# ble_top_secure register map
Vendor: Texas Instruments
Peripheral module from a debugger description file (folder CC35X1).
Registers are 32-bit, read-write, reset 0x0 unless marked. A register's access mark holds for its fields unless they carry their own. Offsets are as the file gives them; lines under a group give offsets from that group; [hi:lo] are bit positions; {n}, {i} and the like mark numbered series; 'fields as' and 'values as' point back to an identical list; <NAME> marks a mode.

## ble_top_secure
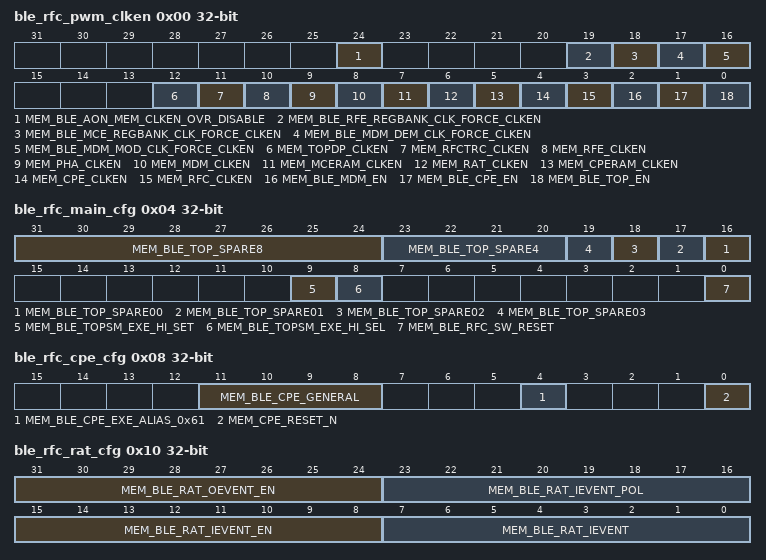
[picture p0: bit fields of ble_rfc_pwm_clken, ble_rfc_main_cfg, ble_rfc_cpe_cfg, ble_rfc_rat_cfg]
0x00 ble_rfc_pwm_clken access per field reset not defined — RF Core Power Management and Clock Enable
  [24] MEM_BLE_AON_MEM_CLKEN_OVR_DISABLE rw — Disable AON Option to Force all CLKEN to '1' on power-up, by ble_aon_mem_clken_ovr (= ble_aon_general[0]). So CLK-EN will be directed controled by BLE_RFC_PWM_CLKEN Fields: MEM_*_CLKEN, as ecpected.
  [19] MEM_BLE_RFE_REGBANK_CLK_FORCE_CLKEN rw — To force RFE REGBANK CLK to be exactly the same as MDM_CLK (as Agama Legacy) set this REG to '1'. Otherwise - for power saving RFE REGBANK CLK will be active only on WRITE Cycles. This REG - cancel RFE REGBANK CLK power saving option.
  [18] MEM_BLE_MCE_REGBANK_CLK_FORCE_CLKEN rw — To force MCE REGBANK CLK to be exactly the same as MDM_CLK (as Agama Legacy) set this REG to '1'. Otherwise - for power saving MCE REGBANK CLK will be active only on WRITE Cycles. This REG - cancel MCE REGBANK CLK power saving option.
  [17] MEM_BLE_MDM_DEM_CLK_FORCE_CLKEN rw — To force DEM_CLK to be exactly the same as MDM_CLK (as Agama Legacy) set this REG to '1'. MDM Demodulator Clock (DEM_CLK) source is MDM_CLK. (controled by mem_mdm_clken). For power saving DEM_CLK Enabled when Demodulator is Enabled by MCE REG: MDMENABLE.demodulator. This REG - Cancel DEM_CLK power saving option.
  [16] MEM_BLE_MDM_MOD_CLK_FORCE_CLKEN rw — To force MOD_CLK to be exactly the same as MDM_CLK (as Agama Legacy) set this REG to '1'. MDM Modulator Clock (MOD_CLK) source is MDM_CLK. (controled by mem_mdm_clken). For power saving MOD_CLK Enabled when Modulator is Enabled by MCE REG: MDMENABLE.modulator. This REG - Cancel MOD_CLK power saving option.
  [12] MEM_TOPDP_CLKEN rw — Enable clock to the TOP Debug-Port module. This module sample the debug-port after the mux out.
  [11] MEM_RFCTRC_CLKEN rw — Enable clock to the RF Core Tracer (RFCTRC) module.
  [10] MEM_RFE_CLKEN rw — Enable clock to the RF Engine (mem_rfe_clken) module.
  [9] MEM_PHA_CLKEN rw — Enable clock to the Packet Handling Accelerator (PHA) module.
  [8] MEM_MDM_CLKEN rw — Enable clock to the Modem (mem_mdm_clken) module.
  [7] MEM_MCERAM_CLKEN rw — Enable clock to the Modem RAM module (includes the MCE RAM).
  [6] MEM_RAT_CLKEN rw — Enable clock to the Radio Timer (RAT) module.
  [5] MEM_CPERAM_CLKEN rw — Enable clock to the Command and Packet Engine (CPE) RAM module. As part of RF Core initialization, set this bit together with CPE bit to enable CPE to boot.
  [4] MEM_CPE_CLKEN rw — Enable processor clock (hclk) to the Command and Packet Engine (mem_cpe_clken) As part of RF Core initialization, set this bit together with mem_cperam_clken to enable CPE to boot.
  [3] MEM_RFC_CLKEN ro — Enable essential clocks for the RF Core interface - This includes: - Interconnect - Radio doorbell - DBELL command interface - Power management (PWR) clock control module - Bus clock (sclk) for the CPE To remove possibility of locking yourself out from the RF Core, this bit can not be cleared. If you need to disable all clocks to the RF Core, see the WLAN.WSOC register: ble_rfc_clken If you need to disable all clocks to the RF Core MDM, see the WLAN.WSOC register: ble_rfc_mdm_clken
  [2] MEM_BLE_MDM_EN rw — MAIN Enable of the MDM Subsystem
  [1] MEM_BLE_CPE_EN rw — MAIN Enable of the CPE Subsystem
  [0] MEM_BLE_TOP_EN rw — MAIN BLE-TOP Enable
0x04 ble_rfc_main_cfg access per field — BLE RF-Core Main Configuration Register
  [31:24] MEM_BLE_TOP_SPARE8 rw — BLE_TOP BTRL Spare Register for ECO
  [23:20] MEM_BLE_TOP_SPARE4 rw — BLE_TOP BTRL Spare Register for ECO
  [n+16] MEM_BLE_TOP_SPARE{n:02} rw (n=0..3) — BLE_TOP BTRL Spare Register for ECO
  [9] MEM_BLE_TOPSM_EXE_HI_SET rw — When BLE_RFC_MAIN_CFG.mem_ble_topsm_exe_hi_sel is set to '1' , control option of TOPsm execution from high section ram (lines 512-1023): 0: MCE TOPsm execution from low section - ram lines 0-511. 1: MCE TOPsm execution from high section - ram lines 512-1023.
  [8] MEM_BLE_TOPSM_EXE_HI_SEL rw — Force option to take control of TOPsm execution from high section ram (lines 512-1023): 0: TOPsm execution from high section set by MCE MDMAPI.protocolmemalloc register. 1: BLE_RFC_MAIN_CFG.mem_ble_topsm_exe_hi_set is controlling execution from high section.
  [0] MEM_BLE_RFC_SW_RESET rw — Force a RF-CORE SW Reset - When this signal set to '1' - it Force '0' on the main RFC Reset
0x08 ble_rfc_cpe_cfg access per field reset not defined — CPE Config register
  [11:8] MEM_BLE_CPE_GENERAL rw — For CPE General Configuratioins. (in Osprey Lx it was connected to BLE_RFC_MAIN_DFG.mem_ble_top_spare4) Bit 0 - Connected as Enable to CPE EDBGRQ. Bit 1 - Spare. Bit 2 - Spare. Bit 3 - Spare.
  [4] MEM_BLE_CPE_EXE_ALIAS_0x61 rw — For protection and correct address space for execution - shift addr to 0x61.
  [0] MEM_CPE_RESET_N rw — CPE Reset_N signal - control the CM0+ main reset: when '0' Reset is active.
0x0C ble_rfc_cpe_irq_ovr wo reset not defined — CPE IRQ Overide option
  [31:0] MEM_BLE_RFC_CPE_IRQ_OVR_WRCL — CPE IRQ Overide Register.
0x10 ble_rfc_rat_cfg — BLE RAT Configuration settings
  [31:24] MEM_BLE_RAT_OEVENT_EN — BLE RF-Core RAT External Output Event Enable bus
  [23:16] MEM_BLE_RAT_IEVENT_POL — BLE RF-Core RAT External Input Event Signal Polarity bus. When a bit is set - the correlated signal is inverted.
  [15:8] MEM_BLE_RAT_IEVENT_EN — BLE RF-Core RAT External Input Event Enable bus
  [7:0] MEM_BLE_RAT_IEVENT — BLE RF-Core RAT External Input Events for Timing synch and controls
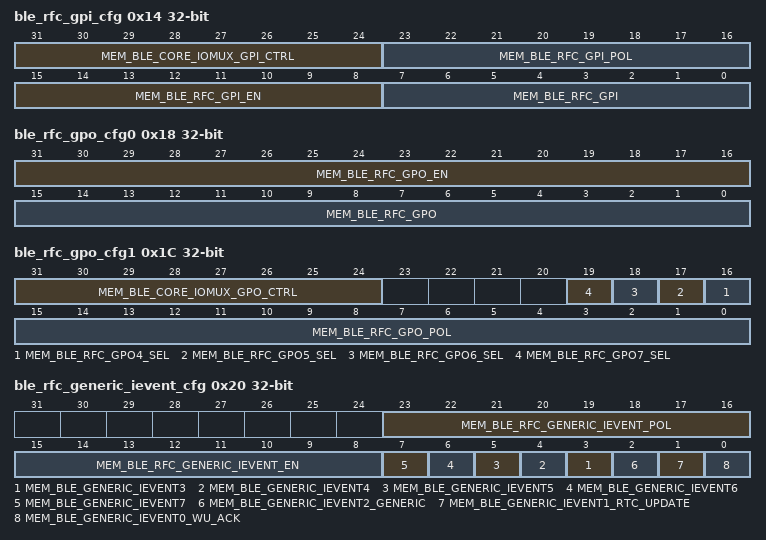
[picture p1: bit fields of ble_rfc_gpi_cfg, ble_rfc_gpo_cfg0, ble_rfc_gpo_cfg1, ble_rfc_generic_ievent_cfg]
0x14 ble_rfc_gpi_cfg — BLE GPI Configuration settings
  [31:24] MEM_BLE_CORE_IOMUX_GPI_CTRL — BLE Option to Control the CORE_IOMUX GPI. This control of external module requiered in order to connect additional BLE-GPI to main SoC IOMUX.
  [23:16] MEM_BLE_RFC_GPI_POL — BLE RF-Core GPI Signal Polarity bus. When a bit is set - the correlated signal is inverted.
  [15:8] MEM_BLE_RFC_GPI_EN — BLE RF-Core GPI Enable bus
  [7:0] MEM_BLE_RFC_GPI — BLE RF-Core GPI Overide by SW values
0x18 ble_rfc_gpo_cfg0 reset not defined — BLE GPO Configuration settings
  [31:16] MEM_BLE_RFC_GPO_EN — BLE RF-Core GPO Enable bus When a bit is set - the correlated signal is Enabled for output I/F.
  [15:0] MEM_BLE_RFC_GPO — BLE RF-Core GPO Overide by SW values
0x1C ble_rfc_gpo_cfg1 access per field — BLE GPO Configuration settings
  [31:24] MEM_BLE_CORE_IOMUX_GPO_CTRL rw — BLE Option to Control the CORE_IOMUX GPO. This control of external module requiered in order to connect additional BLE-GPO to main SoC IOMUX.
  [n+12] MEM_BLE_RFC_GPO{n}_SEL rw (n=4..7) — Selects GPO4: '0' output rfc_gpo[{n}] , '1' output rfc_gpo[{n+4}]
  [15:0] MEM_BLE_RFC_GPO_POL rw — BLE RF-Core GPO Signal Polarity bus. When a bit is set - the correlated signal is inverted for output I/F.
0x20 ble_rfc_generic_ievent_cfg access per field reset not defined — BLE GPI Configuration settings
  [23:16] MEM_BLE_RFC_GENERIC_IEVENT_POL rw — BLE RF-Core GENERIC IEVENT Polarity Signals. When a bit is set - the correlated signal is inverted.
  [15:8] MEM_BLE_RFC_GENERIC_IEVENT_EN rw — BLE RF-Core Generic Input Event Enable bus
  [n] MEM_BLE_GENERIC_IEVENT{n} rw (n=3..7) — BLE RF-Core Generic External Input Event {n:02}
  [2] MEM_BLE_GENERIC_IEVENT2_GENERIC rw — BLE RF-Core Generic External Input Events as RFC Generic Signal
  [1] MEM_BLE_GENERIC_IEVENT1_RTC_UPDATE rw — BLE RF-Core Generic External Input Events as RTC Update (Radio-Time-Control)
  [0] MEM_BLE_GENERIC_IEVENT0_WU_ACK rw — BLE RF-Core Generic External Input Events as RFC WU ACK Signal
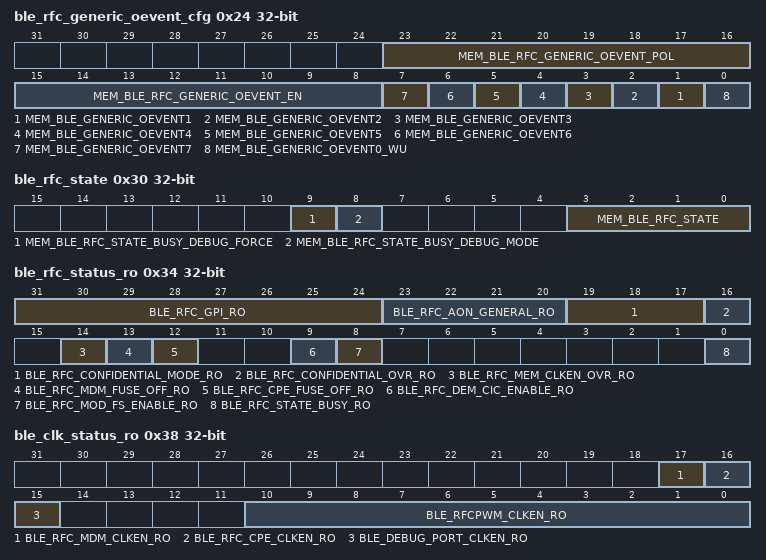
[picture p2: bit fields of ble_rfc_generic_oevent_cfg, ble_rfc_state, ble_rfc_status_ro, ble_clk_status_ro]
0x24 ble_rfc_generic_oevent_cfg access per field — BLE GPI Configuration settings
  [23:16] MEM_BLE_RFC_GENERIC_OEVENT_POL rw — BLE RF-Core GENERIC OEVENT Polarity Signals. When a bit is set - the correlated signal is inverted.
  [15:8] MEM_BLE_RFC_GENERIC_OEVENT_EN rw — BLE RF-Core Generic Output Event Enable bus
  [n] MEM_BLE_GENERIC_OEVENT{n} rw (n=1..7) — BLE RF-Core Generic Output Event 03
  [0] MEM_BLE_GENERIC_OEVENT0_WU rw — BLE RF-Core Generic Output Events as RFC WU Signal
0x30 ble_rfc_state access per field reset not defined — RF-Core State RO Register
  [9] MEM_BLE_RFC_STATE_BUSY_DEBUG_FORCE rw — RF-Core State BUSY indecation to GNS - Debug Option to force its value.
  [8] MEM_BLE_RFC_STATE_BUSY_DEBUG_MODE rw — RF-Core State BUSY indecation to GNS - Debug mode to force its value.
  [3:0] MEM_BLE_RFC_STATE rw — RF-Core State Register (Instead of RDBELL State register)
0x34 ble_rfc_status_ro ro reset not defined — RF-Core Status RO Register
  [31:24] BLE_RFC_GPI_RO — Input to RF-Core Signal: 'ble_rfc_gpi[7:0]' RO Register for Status.
  [23:20] BLE_RFC_AON_GENERAL_RO — AON to RF-Core Signal: 'ble_aon_general[3:4]' RO Register for Status.
  [19:17] BLE_RFC_CONFIDENTIAL_MODE_RO — AON to RF-Core Signal: 'ble_rfc_confidential_mode[2:0]' RO Register for Status.
  [16] BLE_RFC_CONFIDENTIAL_OVR_RO — AON to RF-Core Signal: 'ble_rfc_confidential_ovr' RO Register for Status.
  [14] BLE_RFC_MEM_CLKEN_OVR_RO — BLE_TOP_CTRL Signal, which overide the CLK-EN: 'ble_aon_mem_clken_ovr' RO Register for Status.
  [13] BLE_RFC_MDM_FUSE_OFF_RO — Fuse to RF-Core Signal: 'ble_mdm_fuse_off' RO Register for Status.
  [12] BLE_RFC_CPE_FUSE_OFF_RO — Fuse to RF-Core Signal: 'ble_cpe_fuse_off' RO Register for Status.
  [9] BLE_RFC_DEM_CIC_ENABLE_RO — RF-Core De-Modulator CIC ENABLE RO Register for Status
  [8] BLE_RFC_MOD_FS_ENABLE_RO — RF-Core Modulator FS ENABLE RO Register for Status
  [0] BLE_RFC_STATE_BUSY_RO — RF-Core State BUSY RO Register
0x38 ble_clk_status_ro ro reset not defined — RF-Core Clocks Status RO Register
  [17] BLE_RFC_MDM_CLKEN_RO — BLE Modem Domain CLKEN Status Register.
  [16] BLE_RFC_CPE_CLKEN_RO — BLE CPE Domain CLKEN Status Register.
  [15] BLE_DEBUG_PORT_CLKEN_RO — BLE Debug-Ports CLK Status Register
  [10:0] BLE_RFCPWM_CLKEN_RO — RF-Core Clocks MEM_RFCPWM_CLKEN Status Register.
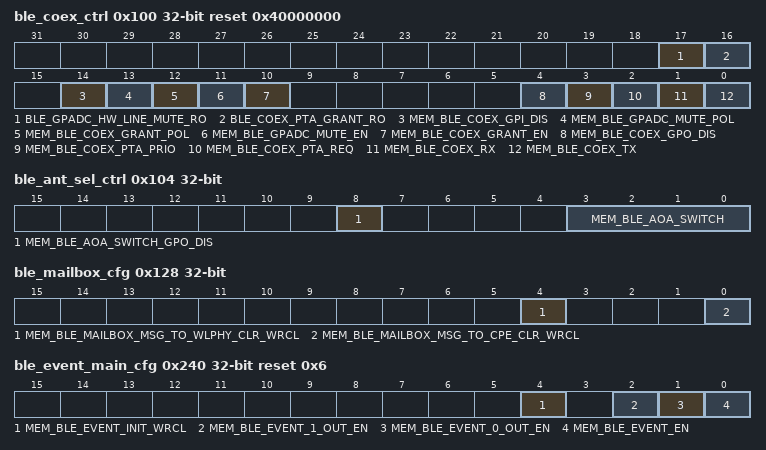
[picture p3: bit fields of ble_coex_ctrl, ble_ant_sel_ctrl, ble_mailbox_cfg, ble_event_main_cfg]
0x100 ble_coex_ctrl access per field reset 0x40000000 (reset mask 0xFFFC0000) — BLE Coex Control
  [17] BLE_GPADC_HW_LINE_MUTE_RO ro — COEX to BLE: PTA GRANT - RO RegiBLE_GPADC_HW_LINE_MUTE_ROter
  [16] BLE_COEX_PTA_GRANT_RO ro — COEX to BLE: PTA GRANT - RO Register
  [14] MEM_BLE_COEX_GPI_DIS rw — BLE to COEX: BLE GPI Signals are DISCONNECTED from Coex Signals. In this mode the Coex may operated by BLE-TOP MMRs.
  [13] MEM_BLE_GPADC_MUTE_POL rw — BLE RF-Core GPADC-MUTE Polarity Signal. When it set to '1' - the GPADC-MUTE Input signal is inverted.
  [12] MEM_BLE_COEX_GRANT_POL rw — BLE RF-Core Coex-Grant Polarity Signal. When it set to '1' - the Coex-Grant Input signal is inverted. By default - Active low, So default is '1'
  [11] MEM_BLE_GPADC_MUTE_EN rw — BLE RF-Core GPADC-MUTE Enable Signal. When it set to '1' - the GPADC-MUTE Input signal is Enabled.
  [10] MEM_BLE_COEX_GRANT_EN rw — BLE RF-Core Coex-Grant Enable Signal. When it set to '1' - the Coex-Grant Input signal is Enabled.
  [4] MEM_BLE_COEX_GPO_DIS rw — BLE to COEX: BLE GPO Signals are DISCONNECTED from Coex Signals. In this mode the Coex may operated by BLE-TOP MMRs.
  [3] MEM_BLE_COEX_PTA_PRIO rw — BLE to COEX: BLE PTA Priority
  [2] MEM_BLE_COEX_PTA_REQ rw — BLE to COEX: BLE PTA Request
  [1] MEM_BLE_COEX_RX rw — BLE to COEX: BLE RX indication
  [0] MEM_BLE_COEX_TX rw — BLE to COEX: BLE TX indication
0x104 ble_ant_sel_ctrl access per field — BLE Antena Select Logic Control
  [8] MEM_BLE_AOA_SWITCH_GPO_DIS rw — BLE to AoA Switch: BLE GPO Signals are DISCONNECTED from AoA Switch Signals. In this mode the A0A Switch may operated by BLE-TOP MMRs.
  [3:0] MEM_BLE_AOA_SWITCH rw — BLE to Antena Select Logic: AoA Switch Select
0x120 ble_mailbox_msg_to_cpe — BLE CRTX MAILBOX - Direction TO CPE
  [31:0] MEM_BLE_MAILBOX_MSG_TO_CPE_WROPT — BLE CRTX MAILBOX From WL-PHY to CPE. When wraiting into this MAILBOX MSG MMR - An IQR is generated towards the CPE.
0x124 ble_mailbox_msg_to_wlphy — BLE CRTX MAILBOX - Direction TO WLPHY
  [31:0] MEM_BLE_MAILBOX_MSG_TO_WLPHY_WROPT — BLE CRTX MAILBOX From CPE to WL-PHY. When wraiting into this MAILBOX MSG MMR - An IQR is generated towards the WL-PHY WMZ.
0x128 ble_mailbox_cfg access per field — BLE CRTX MAILBOX - Direction TO CPE
  [4] MEM_BLE_MAILBOX_MSG_TO_WLPHY_CLR_WRCL wo — Writing to this bit - CLEAR the MAILBOX MSG From CPE to WL-PHY. No IQR is generated.
  [0] MEM_BLE_MAILBOX_MSG_TO_CPE_CLR_WRCL wo — Writing to this bit - CLEAR the MAILBOX MSG From WL-PHY to CPE. No IQR is generated.
0x200 ble_event_in_set wo — BLE Input Events for Timing synch and controls.
  [31:0] MEM_BLE_EVENT_IN_SET_WRCL — BLE TOP Generic Input Events Set option for Timing synch and control
0x204 ble_event_in_clr wo — BLE Input Events for Timing synch and controls.
  [31:0] MEM_BLE_EVENT_IN_CLR_WRCL — BLE TOP Generic Input Events Clear option - Each bit clears its correlated event. Events better be cleared only after event source was cleared (e.g. GPI was de-asserted)
0x208 ble_event_in_mask — BLE Input Events Mask-Enable.
  [31:0] MEM_BLE_EVENT_IN_MASK — BLE Input Events Mask-Enable: mask is active when set to '1' (Mask active means - Event is blocked)
0x20C ble_event_in_sel — BLE Input Events SEL - when active select IRQ-0 when set to '0' and select IRQ-1 when set to '1'
  [31:0] MEM_BLE_EVENT_IN_SEL
0x210 ble_event_in_status_ro ro — BLE Input Events for Timing synch and controls.
  [31:0] BLE_EVENT_IN_STATUS_RO — BLE TOP Input Events STATUS Register (RO Register)
0x220 ble_event_out_set wo — BLE Output Events for Timing synch and controls.
  [31:0] MEM_BLE_EVENT_OUT_SET_WRCL — BLE TOP Generic OUT Events SET option for Timing synch and control
0x224 ble_event_out_clr wo — BLE Output Events for Timing synch and controls.
  [31:0] MEM_BLE_EVENT_OUT_CLR_WRCL — BLE TOP Generic OUT Events Clear option - Each bit clears its correlated event. Events better be cleared only after event source was cleared (e.g. GPO was de-asserted)
0x228 ble_event_out_mask — BLE Output Events Mask-Enable.
  [31:0] MEM_BLE_EVENT_OUT_MASK — BLE Output Events Mask-Enable: mask is active when set to '1'. (Mask active means - Event is blocked)
0x22C ble_event_out_sel reset 0xFFFFFFFF — BLE OUT Events SEL - when active select IRQ-0 when set to '0' and select IRQ-1 when set to '1'
  [31:0] MEM_BLE_EVENT_OUT_SEL
0x230 ble_event_out_status_ro ro — BLE Input Events for Timing synch and controls.
  [31:0] BLE_EVENT_OUT_STATUS_RO — BLE TOP Output Events STATUS Register (RO Register)
0x240 ble_event_main_cfg access per field reset 0x6 — BLE GENERAL EVENT Controls (G1/G2)
  [4] MEM_BLE_EVENT_INIT_WRCL rw — BLE GENERAL EVENT (G1/G2) INIT Control. Pulse Signal. It Reset all the Events (total 64) at once.
  [2] MEM_BLE_EVENT_1_OUT_EN rw — BLE GENERAL EVENT 1 - OUT Enable Control.
  [1] MEM_BLE_EVENT_0_OUT_EN rw — BLE GENERAL EVENT 0 - OUT Enable Control.
  [0] MEM_BLE_EVENT_EN rw — BLE GENERAL EVENT (G1/G2) Enable Control - Enable the Events capture mechanism.
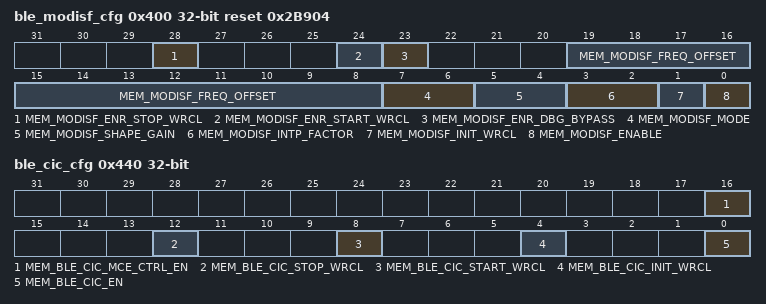
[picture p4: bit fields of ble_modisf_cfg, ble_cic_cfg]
0x400 ble_modisf_cfg access per field reset 0x2B904 — BLE RFEXT MOD-ISF Module CFG Registers. Note: MOD-ISF is known as Tx-Shaper.
  [28] MEM_MODISF_ENR_STOP_WRCL wo — BLE MODISF ENR (Exp-And-Ramp) STOP - Ramp-Down Control option. Pulse Signal
  [24] MEM_MODISF_ENR_START_WRCL wo — BLE MODISF ENR (Exp-And-Ramp) START - Ramp-Up Control option. Pulse Signal
  [23] MEM_MODISF_ENR_DBG_BYPASS rw — BLE MODISF ENR (Exp-And-Ramp) DEBUG OPTION to BYPASS Ramp-Up/Down function. Only EXP function (I/Q convertion) is active.
  [19:8] MEM_MODISF_FREQ_OFFSET rw — BLE RFEXT - MOD-ISF Module - Frequency Offset (offset from base-band).
  [7:6] MEM_MODISF_MODE rw — BLE RFEXT - MOD-ISF Module - Mode od Operation (Protocol)
  [5:4] MEM_MODISF_SHAPE_GAIN rw — BLE RFEXT - MOD-ISF Module - Shape Gain
  [3:2] MEM_MODISF_INTP_FACTOR rw — BLE RFEXT - MOD-ISF Module - Interpolation Factor
  [1] MEM_MODISF_INIT_WRCL wo — BLE RFEXT - MOD-ISF Module - INIT - PULSE.
  [0] MEM_MODISF_ENABLE rw — BLE RFEXT - MOD-ISF Module - ENABLE.
0x404 ble_modisf_shape0 — BLE rfext modisf SHAPING settings mmr - TBD: add additional description
  [31:0] MEM_MODISF_SHAPE0 — BLE rfext modisf cfg mmr - TBD: add additional description
0x408 ble_modisf_shape1 reset 0x5030101 — BLE rfext modisf SHAPING settings mmr - TBD: add additional description
  [31:0] MEM_MODISF_SHAPE1 — BLE rfext modisf cfg mmr - TBD: add additional description
0x40C ble_modisf_shape2 reset 0x1D140D08 — BLE rfext modisf SHAPING settings mmr - TBD: add additional description
  [31:0] MEM_MODISF_SHAPE2 — BLE rfext modisf cfg mmr - TBD: add additional description
0x410 ble_modisf_shape3 reset 0x5D4A392A — BLE rfext modisf SHAPING settings mmr - TBD: add additional description
  [31:0] MEM_MODISF_SHAPE3 — BLE rfext modisf cfg mmr - TBD: add additional description
0x414 ble_modisf_shape4 reset 0xA2938270 — BLE rfext modisf SHAPING settings mmr - TBD: add additional description
  [31:0] MEM_MODISF_SHAPE4 — BLE rfext modisf cfg mmr - TBD: add additional description
0x418 ble_modisf_shape5 reset 0xC0BDB7AE — BLE rfext modisf SHAPING settings mmr - TBD: add additional description
  [31:0] MEM_MODISF_SHAPE5 — BLE rfext modisf cfg mmr - TBD: add additional description
0x420 ble_rfext_inv_vcodivider access per field — BLE rfext INV divider cfg mmr - TBD: add additional description
  [15:0] MEM_INV_VCODIVIDER rw — BLE rfext modisf cfg mmr - TBD: add additional description
0x440 ble_cic_cfg access per field — BLE CIC Controls - Enable and INIT Option.
  [16] MEM_BLE_CIC_MCE_CTRL_EN rw — BLE CIC Enable MCE Control.
  [12] MEM_BLE_CIC_STOP_WRCL rw — BLE CIC STOP Control option. Pulse Signal
  [8] MEM_BLE_CIC_START_WRCL rw — BLE CIC START Control option. Pulse Signal
  [4] MEM_BLE_CIC_INIT_WRCL rw — BLE CIC INIT Control. Pulse Signal
  [0] MEM_BLE_CIC_EN rw — BLE CIC Enable Control.
